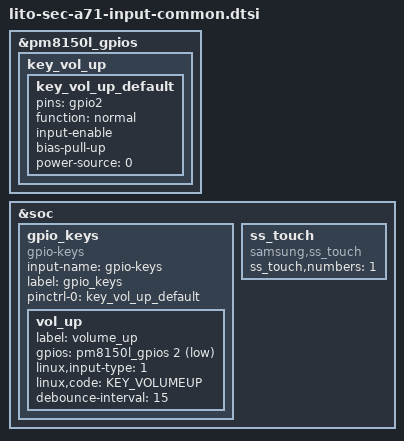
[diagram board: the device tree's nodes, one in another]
/* Copyright (c) 2016-2017, The Linux Foundation. All rights reserved.
 *
 * This program is free software; you can redistribute it and/or modify
 * it under the terms of the GNU General Public License version 2 and
 * only version 2 as published by the Free Software Foundation.
 *
 * This program is distributed in the hope that it will be useful,
 * but WITHOUT ANY WARRANTY; without even the implied warranty of
 * MERCHANTABILITY or FITNESS FOR A PARTICULAR PURPOSE.  See the
 * GNU General Public License for more details.
 */

#include <dt-bindings/input/input.h>

/delete-node/&key_vol_up_default;
&pm8150l_gpios {
	key_vol_up {
		key_vol_up_default: key_vol_up_default {
			pins = "gpio2";
			function = "normal";
			input-enable;
			bias-pull-up;
			power-source = <0>;
		};
	};
};

&soc {
	/delete-node/gpio_keys;
	gpio_keys {
		status = "ok";
		compatible = "gpio-keys";
		input-name = "gpio-keys";
		label = "gpio_keys";

		pinctrl-names = "default";
		pinctrl-0 = <&key_vol_up_default>;

		vol_up {
			label = "volume_up";
			gpios = <&pm8150l_gpios 2 0x1>;
			linux,input-type = <1>;
			linux,code = <KEY_VOLUMEUP>;
			debounce-interval = <15>;
		};
	};

	ss_touch {
		compatible = "samsung,ss_touch";
		ss_touch,numbers = <1>;
	};

};
